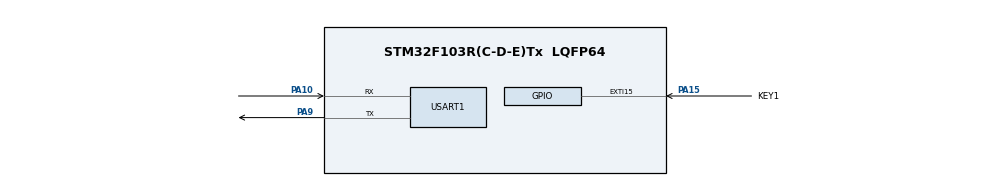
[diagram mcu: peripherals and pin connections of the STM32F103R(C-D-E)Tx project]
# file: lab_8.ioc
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IWDG.Prescaler=IWDG_PRESCALER_64
IWDG.Reload=1250
Mcu.Family=STM32F1
Mcu.Name=STM32F103R(C-D-E)Tx
Mcu.Package=LQFP64
NVIC.EXTI15_10_IRQn=true\:1\:1\:true\:false\:true\:true\:true\:true
NVIC.PriorityGroup=NVIC_PRIORITYGROUP_2
NVIC.TIM3_IRQn=true\:0\:0\:true\:false\:true\:true\:true\:true
NVIC.USART1_IRQn=true\:1\:1\:true\:false\:true\:true\:true\:true
PA10.Mode=Asynchronous
PA10.Signal=USART1_RX
PA13.Mode=Serial_Wire
PA13.Signal=SYS_JTMS-SWDIO
PA14.Mode=Serial_Wire
PA14.Signal=SYS_JTCK-SWCLK
PA15.GPIO_Label=KEY1
PA15.GPIO_ModeDefaultEXTI=GPIO_MODE_IT_FALLING
PA15.GPIO_PuPd=GPIO_PULLUP
PA15.Signal=GPXTI15
PA9.Mode=Asynchronous
PA9.Signal=USART1_TX
PD0-OSC_IN.Mode=HSE-External-Oscillator
PD0-OSC_IN.Signal=RCC_OSC_IN
PD1-OSC_OUT.Mode=HSE-External-Oscillator
PD1-OSC_OUT.Signal=RCC_OSC_OUT
ProjectManager.HeapSize=0x200
ProjectManager.StackSize=0x400
ProjectManager.TargetToolchain=STM32CubeIDE
RCC.APB1Freq_Value=8000000
RCC.APB2Freq_Value=8000000
TIM3.Period=999
TIM3.Prescaler=7199
USART1.VirtualMode=VM_ASYNC
VP_IWDG_VS_IWDG.Mode=IWDG_Activate
VP_TIM3_VS_ClockSourceINT.Mode=Internal
board=custom

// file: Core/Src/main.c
/* USER CODE BEGIN Header */
/**
 ******************************************************************************
 * @file           : main.c
 * @brief          : Main program body
 ******************************************************************************
 * @attention
 *
 * Copyright (c) 2023 STMicroelectronics.
 * All rights reserved.
 *
 * This software is licensed under terms that can be found in the LICENSE file
 * in the root directory of this software component.
 * If no LICENSE file comes with this software, it is provided AS-IS.
 *
 ******************************************************************************
 */
/* USER CODE END Header */
#include "main.h"

/* USER CODE BEGIN Includes */
#include <stdio.h>
#include <string.h>

/* USER CODE END Includes */

IWDG_HandleTypeDef hiwdg;

TIM_HandleTypeDef htim3;

UART_HandleTypeDef huart1;

void SystemClock_Config(void);
static void MX_GPIO_Init(void);
static void MX_IWDG_Init(void);
static void MX_USART1_UART_Init(void);
static void MX_TIM3_Init(void);

int main(void)
{

  /* MCU Configuration--------------------------------------------------------*/

  /* Reset of all peripherals, Initializes the Flash interface and the Systick. */
  HAL_Init();

  /* Configure the system clock */
  SystemClock_Config();

  /* Initialize all configured peripherals */
  MX_GPIO_Init();
  MX_IWDG_Init();
  MX_USART1_UART_Init();
  MX_TIM3_Init();
  /* USER CODE BEGIN 2 */
    HAL_TIM_Base_Start_IT(&htim3);
  /* USER CODE END 2 */

  /* Infinite loop */
  /* USER CODE BEGIN WHILE */
    int i = 0;
    unsigned char msg[100];
    HAL_UART_Transmit(&huart1, "Restart\r\n", 9, HAL_MAX_DELAY);
    while (1) {
    /* USER CODE END WHILE */

    /* USER CODE BEGIN 3 */
        i++;
        sprintf(msg, "i = %d\r\n", i);
        HAL_UART_Transmit(&huart1, (uint8_t *)msg, strlen(msg), HAL_MAX_DELAY);
        HAL_Delay(1000);
    }
  /* USER CODE END 3 */
}

void SystemClock_Config(void)
{
  RCC_OscInitTypeDef RCC_OscInitStruct = {0};
  RCC_ClkInitTypeDef RCC_ClkInitStruct = {0};

  /** Initializes the RCC Oscillators according to the specified parameters
  * in the RCC_OscInitTypeDef structure.
  */
  RCC_OscInitStruct.OscillatorType = RCC_OSCILLATORTYPE_HSI|RCC_OSCILLATORTYPE_LSI;
  RCC_OscInitStruct.HSIState = RCC_HSI_ON;
  RCC_OscInitStruct.HSICalibrationValue = RCC_HSICALIBRATION_DEFAULT;
  RCC_OscInitStruct.LSIState = RCC_LSI_ON;
  RCC_OscInitStruct.PLL.PLLState = RCC_PLL_NONE;
  if (HAL_RCC_OscConfig(&RCC_OscInitStruct) != HAL_OK)
  {
    Error_Handler();
  }

  /** Initializes the CPU, AHB and APB buses clocks
  */
  RCC_ClkInitStruct.ClockType = RCC_CLOCKTYPE_HCLK|RCC_CLOCKTYPE_SYSCLK
                              |RCC_CLOCKTYPE_PCLK1|RCC_CLOCKTYPE_PCLK2;
  RCC_ClkInitStruct.SYSCLKSource = RCC_SYSCLKSOURCE_HSI;
  RCC_ClkInitStruct.AHBCLKDivider = RCC_SYSCLK_DIV1;
  RCC_ClkInitStruct.APB1CLKDivider = RCC_HCLK_DIV1;
  RCC_ClkInitStruct.APB2CLKDivider = RCC_HCLK_DIV1;

  if (HAL_RCC_ClockConfig(&RCC_ClkInitStruct, FLASH_LATENCY_0) != HAL_OK)
  {
    Error_Handler();
  }
}

static void MX_IWDG_Init(void)
{

  hiwdg.Instance = IWDG;
  hiwdg.Init.Prescaler = IWDG_PRESCALER_64;
  hiwdg.Init.Reload = 1250;
  if (HAL_IWDG_Init(&hiwdg) != HAL_OK)
  {
    Error_Handler();
  }

}

static void MX_TIM3_Init(void)
{

  TIM_ClockConfigTypeDef sClockSourceConfig = {0};
  TIM_MasterConfigTypeDef sMasterConfig = {0};

  htim3.Instance = TIM3;
  htim3.Init.Prescaler = 7199;
  htim3.Init.CounterMode = TIM_COUNTERMODE_UP;
  htim3.Init.Period = 999;
  htim3.Init.ClockDivision = TIM_CLOCKDIVISION_DIV1;
  htim3.Init.AutoReloadPreload = TIM_AUTORELOAD_PRELOAD_DISABLE;
  if (HAL_TIM_Base_Init(&htim3) != HAL_OK)
  {
    Error_Handler();
  }
  sClockSourceConfig.ClockSource = TIM_CLOCKSOURCE_INTERNAL;
  if (HAL_TIM_ConfigClockSource(&htim3, &sClockSourceConfig) != HAL_OK)
  {
    Error_Handler();
  }
  sMasterConfig.MasterOutputTrigger = TIM_TRGO_RESET;
  sMasterConfig.MasterSlaveMode = TIM_MASTERSLAVEMODE_DISABLE;
  if (HAL_TIMEx_MasterConfigSynchronization(&htim3, &sMasterConfig) != HAL_OK)
  {
    Error_Handler();
  }

}

static void MX_USART1_UART_Init(void)
{

  huart1.Instance = USART1;
  huart1.Init.BaudRate = 115200;
  huart1.Init.WordLength = UART_WORDLENGTH_8B;
  huart1.Init.StopBits = UART_STOPBITS_1;
  huart1.Init.Parity = UART_PARITY_NONE;
  huart1.Init.Mode = UART_MODE_TX_RX;
  huart1.Init.HwFlowCtl = UART_HWCONTROL_NONE;
  huart1.Init.OverSampling = UART_OVERSAMPLING_16;
  if (HAL_UART_Init(&huart1) != HAL_OK)
  {
    Error_Handler();
  }

}

static void MX_GPIO_Init(void)
{
  GPIO_InitTypeDef GPIO_InitStruct = {0};

  /* GPIO Ports Clock Enable */
  __HAL_RCC_GPIOD_CLK_ENABLE();
  __HAL_RCC_GPIOA_CLK_ENABLE();

  /*Configure GPIO pin : KEY1_Pin */
  GPIO_InitStruct.Pin = KEY1_Pin;
  GPIO_InitStruct.Mode = GPIO_MODE_IT_FALLING;
  GPIO_InitStruct.Pull = GPIO_PULLUP;
  HAL_GPIO_Init(KEY1_GPIO_Port, &GPIO_InitStruct);

  /* EXTI interrupt init*/
  HAL_NVIC_SetPriority(EXTI15_10_IRQn, 1, 1);
  HAL_NVIC_EnableIRQ(EXTI15_10_IRQn);

}

void Error_Handler(void)
{
  /* USER CODE BEGIN Error_Handler_Debug */
    /* User can add his own implementation to report the HAL error return state
     */
    __disable_irq();
    while (1) {
    }
  /* USER CODE END Error_Handler_Debug */
}

#ifdef  USE_FULL_ASSERT
/**
  * @brief  Reports the name of the source file and the source line number
  *         where the assert_param error has occurred.
  * @param  file: pointer to the source file name
  * @param  line: assert_param error line source number
  * @retval None
  */
void assert_failed(uint8_t *file, uint32_t line)
{
  /* USER CODE BEGIN 6 */
    /* User can add his own implementation to report the file name and line
       number, ex: printf("Wrong parameters value: file %s on line %d\r\n",
       file, line) */
  /* USER CODE END 6 */
}
#endif /* USE_FULL_ASSERT */
